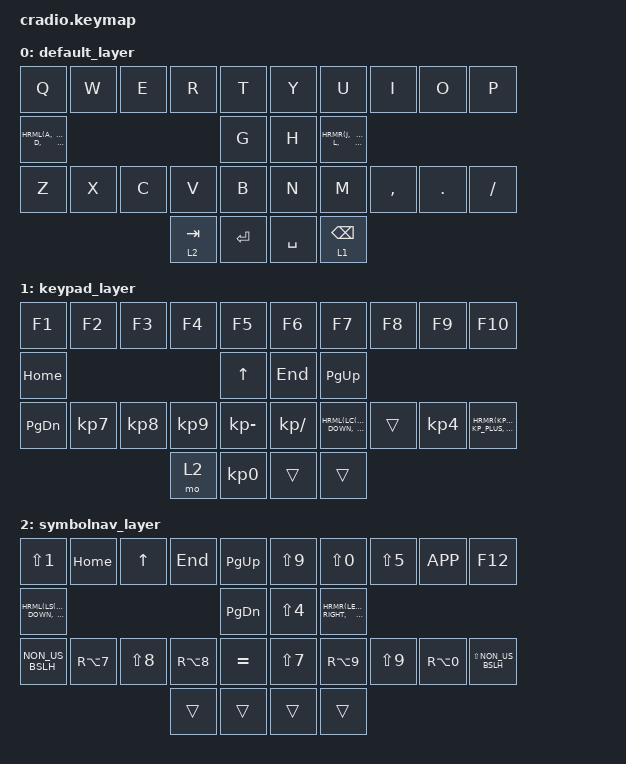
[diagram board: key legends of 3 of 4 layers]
// Copyright (c) 2022 The ZMK Contributors
// SPDX-License-Identifier: MIT
//
// Ported from go60 keymap (Norwegian layout)

#include <behaviors.dtsi>
#include <dt-bindings/zmk/keys.h>
#include <dt-bindings/zmk/bt.h>
#include <dt-bindings/zmk/outputs.h>

// Home row mods macro
// Order matches go60: LGUI (pinky) → LALT → LCTRL → LSHFT (index)
#define HRML(k1,k2,k3,k4) &ht LGUI k1  &ht LALT k2  &ht LCTRL k3  &ht LSHFT k4
#define HRMR(k1,k2,k3,k4) &ht RSHFT k1  &ht RCTRL k2  &ht RALT k3  &ht RGUI k4

/ {
    behaviors {
        ht: hold_tap {
            compatible = "zmk,behavior-hold-tap";
            #binding-cells = <2>;
            flavor = "tap-preferred";
            tapping-term-ms = <220>;
            quick-tap-ms = <150>;
            require-prior-idle-ms = <100>;
            bindings = <&kp>, <&kp>;
        };
    };

    conditional_layers {
        compatible = "zmk,conditional-layers";
        tri_layer {
            if-layers = <1 2>;
            then-layer = <3>;
        };
    };

    keymap {
        compatible = "zmk,keymap";

        // Base layer — matches go60 Base (inner 5 cols per side, rows 2-4)
        default_layer {
            bindings = <
        //╭──────────┬──────────┬──────────┬──────────┬──────────╮   ╭──────────┬──────────┬──────────┬──────────┬──────────╮
        //│  Q       │  W       │  E       │  R       │  T       │   │  Y       │  U       │  I       │  O       │  P       │
            &kp Q      &kp W      &kp E      &kp R      &kp T          &kp Y      &kp U      &kp I      &kp O      &kp P
        //├──────────┼──────────┼──────────┼──────────┼──────────┤   ├──────────┼──────────┼──────────┼──────────┼──────────┤
        //│  A/LGUI  │  S/LALT  │  D/LCTRL │  F/LSHFT │  G       │   │  H       │  J/RSHFT │  K/RCTRL │  L/RALT  │  ;/RGUI  │
            HRML(A,        S,         D,         F)     &kp G          &kp H      HRMR(J,        K,         L,        SEMI)
        //├──────────┼──────────┼──────────┼──────────┼──────────┤   ├──────────┼──────────┼──────────┼──────────┼──────────┤
        //│  Z       │  X       │  C       │  V       │  B       │   │  N       │  M       │ ,        │ .        │ /        │
            &kp Z      &kp X      &kp C      &kp V      &kp B          &kp N      &kp M      &kp COMMA  &kp DOT    &kp FSLH
        //╰──────────┴──────────┴──────────┼──────────┼──────────┤   ├──────────┼──────────┼──────────┴──────────┴──────────╯
        //                                 │SymNav/TAB│  ENTER   │   │  SPACE   │ KP/BSPC  │
                                            &lt 2 TAB  &kp RET        &kp SPACE  &lt 1 BSPC
        //                                 ╰──────────┴──────────╯   ╰──────────┴──────────╯
            >;
        };

        // Keypad layer (layer 1) — matches go60 Keypad layer
        keypad_layer {
            bindings = <
        //╭──────────┬──────────┬──────────┬──────────┬──────────╮   ╭──────────┬──────────┬──────────┬──────────┬──────────╮
        //│  F1      │  F2      │  F3      │  F4      │  F5      │   │  F6      │  F7      │  F8      │  F9      │  F10     │
            &kp F1     &kp F2     &kp F3     &kp F4     &kp F5         &kp F6     &kp F7     &kp F8     &kp F9     &kp F10
        //├──────────┼──────────┼──────────┼──────────┼──────────┤   ├──────────┼──────────┼──────────┼──────────┼──────────┤
        //│  HOME    │  UP      │  END     │  PG_UP   │  PG_DN   │   │  KP 7    │  KP 8    │  KP 9    │  KP -    │  KP /    │
            &kp HOME   &kp UP     &kp END    &kp PG_UP  &kp PG_DN      &kp KP_N7  &kp KP_N8  &kp KP_N9  &kp KP_MINUS &kp KP_SLASH
        //├──────────┼──────────┼──────────┼──────────┼──────────┤   ├──────────┼──────────┼──────────┼──────────┼──────────┤
        //│ LC(Y)/GUI│ LEFT/ALT │ DOWN/CTRL│RIGHT/SHFT│          │   │  KP 4    │  KP 5/SFT│  KP 6/CTL│  KP +/ALT│  KP */GUI│
            HRML(LC(Y),  LEFT,      DOWN,      RIGHT)   &trans         &kp KP_N4  HRMR(KP_N5,  KP_N6,     KP_PLUS,   KP_MULTIPLY)
        //╰──────────┴──────────┴──────────┼──────────┼──────────┤   ├──────────┼──────────┼──────────┴──────────┴──────────╯
        //                                 │SymNav mo │  KP 0    │   │          │          │
                                            &mo 2      &kp KP_N0      &trans     &trans
        //                                 ╰──────────┴──────────╯   ╰──────────┴──────────╯
            >;
        };

        // SymbolNav layer (layer 2) — matches go60 SymbolNav layer (Norwegian layout)
        symbolnav_layer {
            bindings = <
        //╭──────────┬──────────┬──────────┬──────────┬──────────╮   ╭──────────┬──────────┬──────────┬──────────┬──────────╮
        //│  ! (S+1) │  HOME    │  UP      │  END     │  PG_UP   │   │  ( (S+9) │  ) (S+0) │  % (S+5) │  APP     │  F12     │
           &kp LS(N1)  &kp HOME   &kp UP     &kp END    &kp PG_UP     &kp LS(N9) &kp LS(N0) &kp LS(N5) &kp K_APP  &kp F12
        //├──────────┼──────────┼──────────┼──────────┼──────────┤   ├──────────┼──────────┼──────────┼──────────┼──────────┤
        //│ @(S+2)/GU│ LEFT/ALT │ DOWN/CTRL│RIGHT/SHFT│  PG_DN   │   │  $ (S+4) │ LEFT/SHFT│DOWN/CTRL │RIGHT/ALT │PAUSE/GUI │
           HRML(LS(N2), LEFT,      DOWN,      RIGHT)    &kp PG_DN     &kp LS(N4) HRMR(LEFT,   DOWN,      RIGHT,     PAUSE_BREAK)
        //├──────────┼──────────┼──────────┼──────────┼──────────┤   ├──────────┼──────────┼──────────┼──────────┼──────────┤
        //│ NUS_BSLH │ RA(7) {  │ S+8 [    │ RA(8) ]  │  = +     │   │  / (S+7) │ RA(9) }  │ ( (S+9)  │ RA(0) \  │ S(NBSLH) │
          &kp NON_US_BSLH &kp RA(N7) &kp LS(N8) &kp RA(N8) &kp EQUAL  &kp LS(N7) &kp RA(N9) &kp LS(N9) &kp RA(N0) &kp LS(NON_US_BSLH)
        //╰──────────┴──────────┴──────────┼──────────┼──────────┤   ├──────────┼──────────┼──────────┴──────────┴──────────╯
                                             &trans     &trans         &trans     &trans
        //                                 ╰──────────┴──────────╯   ╰──────────┴──────────╯
            >;
        };

        // Magic/System layer (layer 3) — activated by holding both thumb keys
        magic_layer {
            bindings = <
        //╭──────────┬──────────┬──────────┬──────────┬──────────╮   ╭──────────┬──────────┬──────────┬──────────┬──────────╮
        //│ RESET    │          │          │          │PROFILE 0 │   │          │          │          │          │  RESET   │
           &sys_reset  &trans     &trans     &trans    &bt BT_SEL 0    &trans     &trans     &trans     &trans    &sys_reset
        //├──────────┼──────────┼──────────┼──────────┼──────────┤   ├──────────┼──────────┼──────────┼──────────┼──────────┤
        //│BOOTLOADER│          │          │          │PROFILE 1 │   │          │          │          │          │BOOTLOADER│
          &bootloader  &trans     &trans     &trans    &bt BT_SEL 1    &trans     &trans     &trans     &trans    &bootloader
        //├──────────┼──────────┼──────────┼──────────┼──────────┤   ├──────────┼──────────┼──────────┼──────────┼──────────┤
        //│OUT USB   │          │          │ CLEAR BT │PROFILE 2 │   │          │          │          │          │OUT BLE   │
          &out OUT_USB &trans     &trans    &bt BT_CLR &bt BT_SEL 2    &trans     &trans     &trans     &trans   &out OUT_BLE
        //╰──────────┴──────────┴──────────┼──────────┼──────────┤   ├──────────┼──────────┼──────────┴──────────┴──────────╯
                                             &trans     &trans         &trans     &trans
        //                                 ╰──────────┴──────────╯   ╰──────────┴──────────╯
            >;
        };
    };
};
